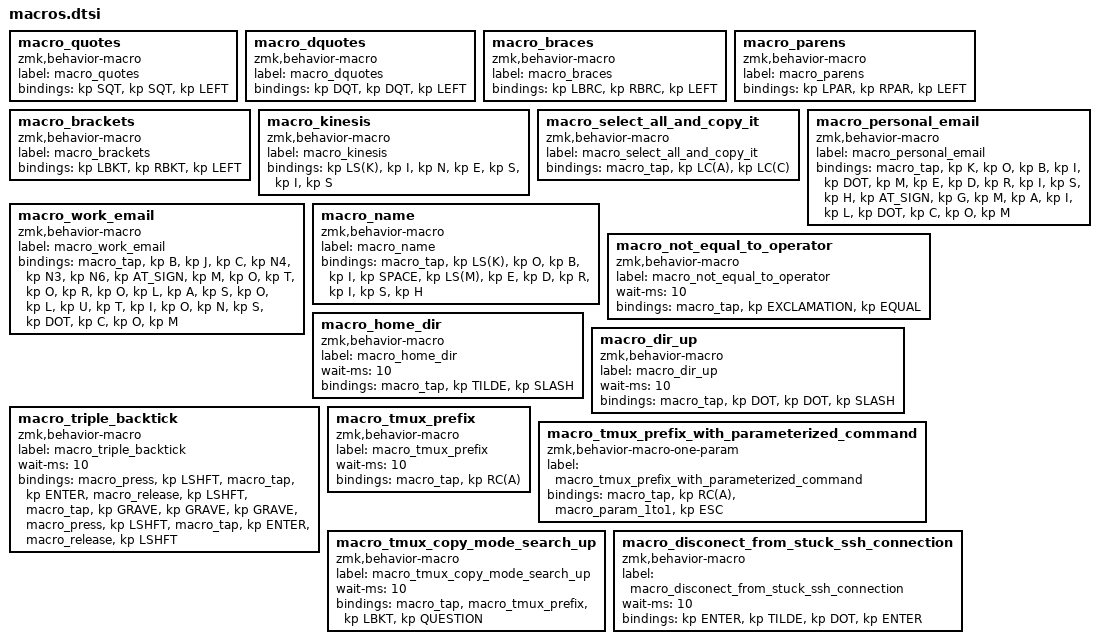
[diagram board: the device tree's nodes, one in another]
  macro_quotes: macro_quotes {
    compatible = "zmk,behavior-macro";
    label = "macro_quotes";
    #binding-cells = <0>;
    bindings = <&kp SQT>, <&kp SQT>, <&kp LEFT>;
  };
  macro_dquotes: macro_dquotes {
    compatible = "zmk,behavior-macro";
    label = "macro_dquotes";
    #binding-cells = <0>;
    bindings = <&kp DQT>, <&kp DQT>, <&kp LEFT>;
  };
  macro_braces: macro_braces {
    compatible = "zmk,behavior-macro";
    label = "macro_braces";
    #binding-cells = <0>;
    bindings = <&kp LBRC>, <&kp RBRC>, <&kp LEFT>;
  };
  macro_parens: macro_parens {
    compatible = "zmk,behavior-macro";
    label = "macro_parens";
    #binding-cells = <0>;
    bindings = <&kp LPAR>, <&kp RPAR>, <&kp LEFT>;
  };
  macro_brackets: macro_brackets {
    compatible = "zmk,behavior-macro";
    label = "macro_brackets";
    #binding-cells = <0>;
    bindings = <&kp LBKT>, <&kp RBKT>, <&kp LEFT>;
  };
  macro_kinesis: macro_kinesis {
    compatible = "zmk,behavior-macro";
    label = "macro_kinesis";
    #binding-cells = <0>;
    bindings = <&kp LS(K)>, <&kp I>, <&kp N>, <&kp E>, <&kp S>, <&kp I>, <&kp S>;
  };
  macro_select_all_and_copy_it: macro_select_all_and_copy_it {
    compatible = "zmk,behavior-macro";
    label = "macro_select_all_and_copy_it";
    #binding-cells = <0>;
    bindings = <&macro_tap &kp LC(A) &kp LC(C)>;
  };
  macro_personal_email: macro_personal_email {
    compatible = "zmk,behavior-macro";
    label = "macro_personal_email";
    #binding-cells = <0>;
    bindings = <&macro_tap &kp K &kp O &kp B &kp I &kp DOT &kp M &kp E &kp D &kp R &kp I &kp S &kp H &kp AT_SIGN &kp G &kp M &kp A &kp I &kp L &kp DOT &kp C &kp O &kp M>;
  };
  macro_work_email: macro_work_email {
    compatible = "zmk,behavior-macro";
    label = "macro_work_email";
    #binding-cells = <0>;
    bindings = <&macro_tap &kp B &kp J &kp C &kp N4 &kp N3 &kp N6 &kp AT_SIGN &kp M &kp O &kp T &kp O &kp R &kp O &kp L &kp A &kp S &kp O &kp L &kp U &kp T &kp I &kp O &kp N &kp S &kp DOT &kp C &kp O &kp M>;
  };

  macro_name: macro_name {
    compatible = "zmk,behavior-macro";
    label = "macro_name";
    #binding-cells = <0>;
    bindings = <&macro_tap &kp LS(K) &kp O &kp B &kp I &kp SPACE &kp LS(M) &kp E &kp D &kp R &kp I &kp S &kp H>;
  };

  macro_not_equal_to_operator: macro_not_equal_to_operator {
    compatible = "zmk,behavior-macro";
    label = "macro_not_equal_to_operator";
    #binding-cells = <0>;
    wait-ms = <10>;
    bindings = <&macro_tap &kp EXCLAMATION &kp EQUAL>;
  };
  macro_home_dir: macro_home_dir {
    compatible = "zmk,behavior-macro";
    label = "macro_home_dir";
    #binding-cells = <0>;
    wait-ms = <10>;
    bindings = <&macro_tap &kp TILDE &kp SLASH >;
  };
  macro_dir_up: macro_dir_up {
    compatible = "zmk,behavior-macro";
    label = "macro_dir_up";
    #binding-cells = <0>;
    wait-ms = <10>;
    bindings = <&macro_tap &kp DOT &kp DOT &kp SLASH>;
  };

  macro_triple_backtick: macro_triple_backtick {
    compatible = "zmk,behavior-macro";
    label = "macro_triple_backtick";
    #binding-cells = <0>;
    wait-ms = <10>;
    bindings = <&macro_press &kp LSHFT>, <&macro_tap &kp ENTER>, <&macro_release &kp LSHFT>, <&macro_tap &kp GRAVE &kp GRAVE &kp GRAVE>, <&macro_press &kp LSHFT>, <&macro_tap &kp ENTER>, <&macro_release &kp LSHFT>;
  };


  // tmux layer macros
  // =================
  macro_tmux_prefix: macro_tmux_prefix {
    compatible = "zmk,behavior-macro";
    label = "macro_tmux_prefix";
    #binding-cells = <0>;
    wait-ms = <10>;
    bindings = <&macro_tap &kp RC(A)>;
  };

  // if no parameter provided then the default is ESC
  macro_tmux_prefix_with_parameterized_command: macro_tmux_prefix_with_parameterized_command {
    compatible = "zmk,behavior-macro-one-param";
    label = "macro_tmux_prefix_with_parameterized_command";
    #binding-cells = <1>;
    bindings = <&macro_tap &kp RC(A)>, <&macro_param_1to1>, <&kp ESC>;
  };

  // copy mode in tmux using the yank plugin
  macro_tmux_copy_mode_search_up: macro_tmux_copy_mode_search_up {
    compatible = "zmk,behavior-macro";
    label = "macro_tmux_copy_mode_search_up";
    #binding-cells = <0>;
    wait-ms = <10>;
    bindings = <&macro_tap &macro_tmux_prefix &kp LBKT &kp QUESTION>;
  };
  // =================

  macro_disconect_from_stuck_ssh_connection: macro_disconect_from_stuck_ssh_connection {
    compatible = "zmk,behavior-macro";
    label = "macro_disconect_from_stuck_ssh_connection";
    #binding-cells = <0>;
    wait-ms = <10>;
    bindings = <&kp ENTER>, <&kp TILDE>, <&kp DOT>, <&kp ENTER>;
  };
